# ES32F0xx register map
File version: 1.0
Registers are 32-bit, read-write, reset 0x0 unless marked. A register's access mark holds for its fields unless they carry their own. Offsets are from the block's base; [hi:lo] are bit positions; {n}, {i} and the like mark numbered series.

## GPIOA — General purpose I/O
Base 0x40084000
Same registers: GPIOB 0x40084040, GPIOC 0x40084080, GPIOD 0x400840C0, GPIOE 0x40084100, GPIOF 0x40084140, GPIOG 0x40084180, GPIOH 0x400841C0
0x00 DIN read
  [15:0] DIN
0x04 DOUT
  [15:0] DOUT
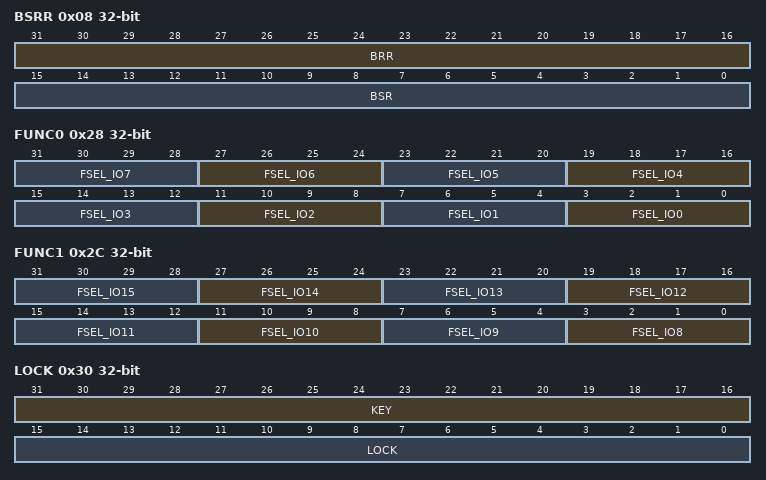
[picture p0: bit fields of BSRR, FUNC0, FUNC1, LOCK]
0x08 BSRR write
  [31:16] BRR, [15:0] BSR
0x0C BIR write
  [15:0] BIR
0x10 MODE
0x14 ODOS
0x18 PUPD
0x1C ODRV reset 0xAAAAAAAA
0x20 FLT
  [15:0] FLT
0x24 TYPE
  [15:0] TYPE
0x28 FUNC0
  [4n+3:4n] FSEL_IO{n} (n=0..7)
0x2C FUNC1
  [4n-29:4n-32] FSEL_IO{n} (n=8..15)
0x30 LOCK
  [31:16] KEY, [15:0] LOCK

## EXTI — External Interrupt
Base 0x40084300
0x00 EXTIRER
  [15:0] EXTIRER
0x08 EXTIFER
  [15:0] EXTIFER
0x10 EXTIEN
  [15:0] EXTIEN
0x18 EXTIFLAG read
  [15:0] EXTIFLAG
0x20 EXTISFR write
  [15:0] EXTISFR
0x28 EXTICFR write
  [15:0] EXTICFR
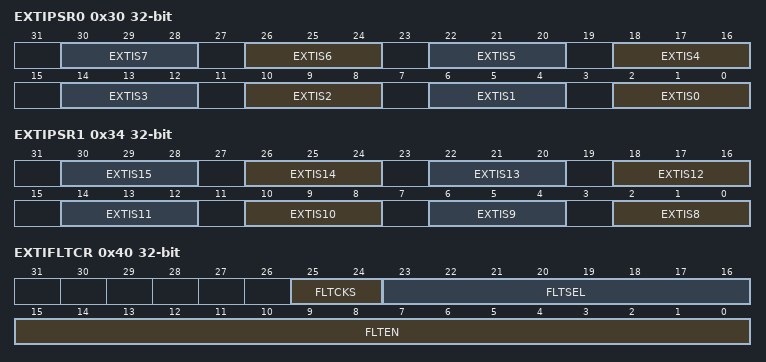
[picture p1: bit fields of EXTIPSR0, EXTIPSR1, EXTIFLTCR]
0x30 EXTIPSR0
  [4n+2:4n] EXTIS{n} (n=0..7)
0x34 EXTIPSR1
  [4n-30:4n-32] EXTIS{n} (n=8..15)
0x40 EXTIFLTCR
  [25:24] FLTCKS, [23:16] FLTSEL, [15:0] FLTEN

## AD16C4T0 — Timer 0
Base 0x40000000
Same registers: BS16T0 0x40000400, GP16C2T0 0x40000800, GP16C2T1 0x40000C00, BS16T1 0x40001000, BS16T2 0x40001400, GP16C4T0 0x40001800, BS16T3 0x40001C00
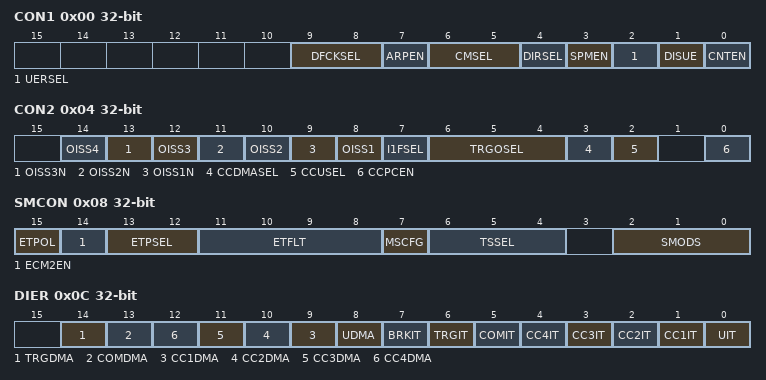
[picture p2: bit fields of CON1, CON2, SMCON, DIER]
0x00 CON1
  [9:8] DFCKSEL, [7] ARPEN, [6:5] CMSEL, [4] DIRSEL, [3] SPMEN, [2] UERSEL, [1] DISUE, [0] CNTEN
0x04 CON2
  [2n+6] OISS{n} (n=1..4), [13] OISS3N, [11] OISS2N, [9] OISS1N, [7] I1FSEL, [6:4] TRGOSEL, [3] CCDMASEL, [2] CCUSEL, [0] CCPCEN
0x08 SMCON
  [15] ETPOL, [14] ECM2EN, [13:12] ETPSEL, [11:8] ETFLT, [7] MSCFG, [6:4] TSSEL, [2:0] SMODS
0x0C DIER write
  [14] TRGDMA, [13] COMDMA, [n+8] CC{n}DMA (n=1..4), [8] UDMA, [7] BRKIT, [6] TRGIT, [5] COMIT, [n] CC{n}IT (n=1..4), [0] UIT
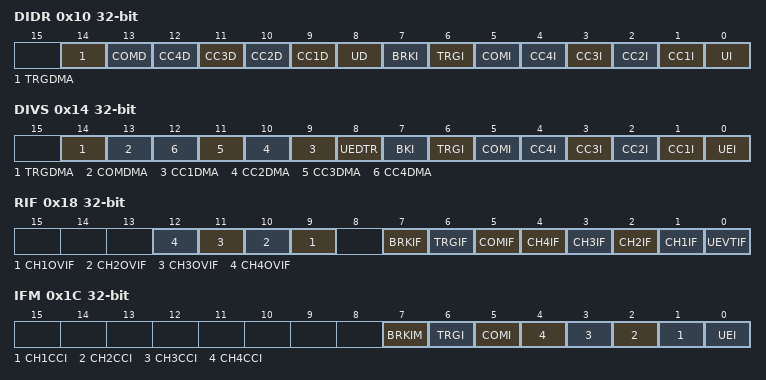
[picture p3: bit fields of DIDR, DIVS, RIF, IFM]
0x10 DIDR write
  [14] TRGDMA, [13] COMD, [n+8] CC{n}D (n=1..4), [8] UD, [7] BRKI, [6] TRGI, [5] COMI, [n] CC{n}I (n=1..4), [0] UI
0x14 DIVS read
  [14] TRGDMA, [13] COMDMA, [n+8] CC{n}DMA (n=1..4), [8] UEDTR, [7] BKI, [6] TRGI, [5] COMI, [n] CC{n}I (n=1..4), [0] UEI
0x18 RIF read
  [n+8] CH{n}OVIF (n=1..4), [7] BRKIF, [6] TRGIF, [5] COMIF, [n] CH{n}IF (n=1..4), [0] UEVTIF
0x1C IFM read
  [7] BRKIM, [6] TRGI, [5] COMI, [n] CH{n}CCI (n=1..4), [0] UEI
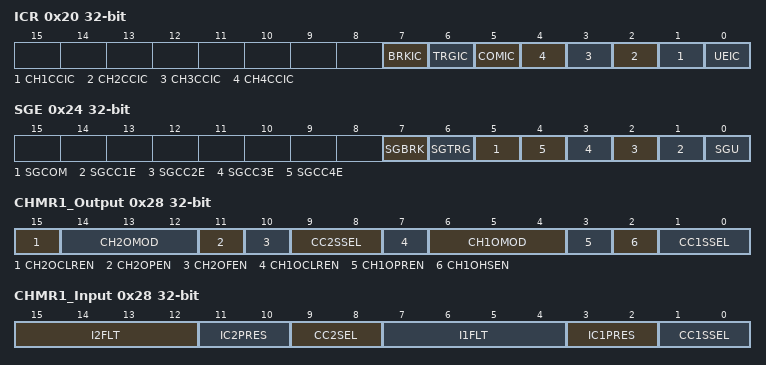
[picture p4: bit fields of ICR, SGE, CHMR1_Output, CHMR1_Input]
0x20 ICR write
  [7] BRKIC, [6] TRGIC, [5] COMIC, [n] CH{n}CCIC (n=1..4), [0] UEIC
0x24 SGE write
  [7] SGBRK, [6] SGTRG, [5] SGCOM, [n] SGCC{n}E (n=1..4), [0] SGU
0x28 CHMR1_Output
  [15] CH2OCLREN, [14:12] CH2OMOD, [11] CH2OPEN, [10] CH2OFEN, [9:8] CC2SSEL, [7] CH1OCLREN, [6:4] CH1OMOD, [3] CH1OPREN, [2] CH1OHSEN, [1:0] CC1SSEL
0x28 CHMR1_Input (alternate view of CHMR1_Output)
  [15:12] I2FLT, [11:10] IC2PRES, [9:8] CC2SEL, [7:4] I1FLT, [3:2] IC1PRES, [1:0] CC1SSEL
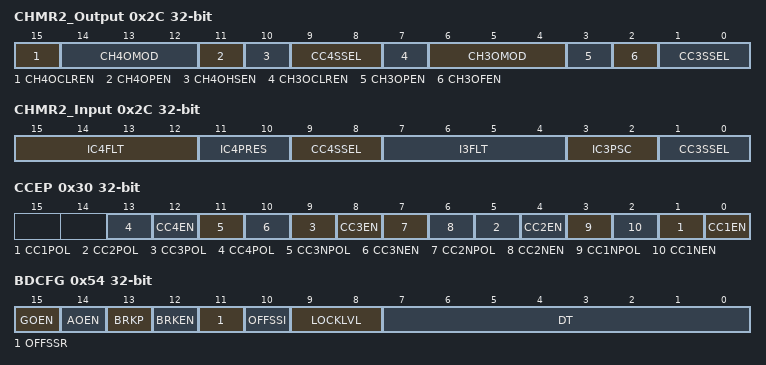
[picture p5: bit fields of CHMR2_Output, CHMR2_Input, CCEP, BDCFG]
0x2C CHMR2_Output
  [15] CH4OCLREN, [14:12] CH4OMOD, [11] CH4OPEN, [10] CH4OHSEN, [9:8] CC4SSEL, [7] CH3OCLREN, [6:4] CH3OMOD, [3] CH3OPEN, [2] CH3OFEN, [1:0] CC3SSEL
0x2C CHMR2_Input (alternate view of CHMR2_Output)
  [15:12] IC4FLT, [11:10] IC4PRES, [9:8] CC4SSEL, [7:4] I3FLT, [3:2] IC3PSC, [1:0] CC3SSEL
0x30 CCEP
  [4n-3] CC{n}POL (n=1..4), [4n-4] CC{n}EN (n=1..4), [11] CC3NPOL, [10] CC3NEN, [7] CC2NPOL, [6] CC2NEN, [3] CC1NPOL, [2] CC1NEN
0x34 COUNT
  [15:0] CNTV
0x38 PRES
  [15:0] PSCV
0x3C AR
  [15:0] ARRV
0x40 REPAR
  [7:0] REPV
{0x40+4i} CCVAL{i} (i=1..4)
  [15:0] CCRV{i}
0x54 BDCFG
  [15] GOEN, [14] AOEN, [13] BRKP, [12] BRKEN, [11] OFFSSR, [10] OFFSSI, [9:8] LOCKLVL, [7:0] DT

## SPI0 — Serial Peripheral Interface
Base 0x40006000
Same registers: SPI1 0x40006400, SPI2 0x40006800
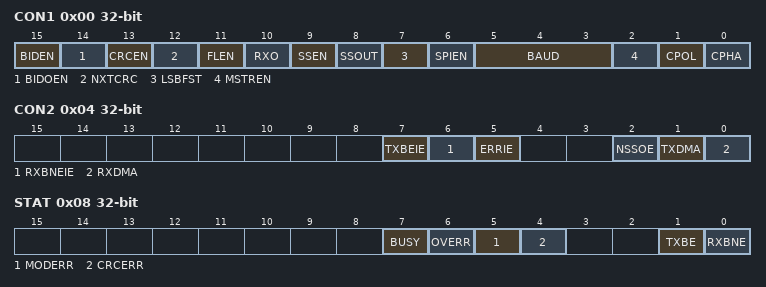
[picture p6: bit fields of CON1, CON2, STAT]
0x00 CON1
  [15] BIDEN, [14] BIDOEN, [13] CRCEN, [12] NXTCRC, [11] FLEN, [10] RXO, [9] SSEN, [8] SSOUT, [7] LSBFST, [6] SPIEN, [5:3] BAUD, [2] MSTREN, [1] CPOL, [0] CPHA
0x04 CON2
  [7] TXBEIE, [6] RXBNEIE, [5] ERRIE, [2] NSSOE, [1] TXDMA, [0] RXDMA
0x08 STAT read
  [7] BUSY, [6] OVERR, [5] MODERR, [4] CRCERR, [1] TXBE, [0] RXBNE
0x0C DATA
  [15:0] VALUE
0x10 CRCPOLY reset 0x7
  [15:0] VALUE
0x14 RXCRC read
  [15:0] CRCVAL
0x18 TXCRC read
  [15:0] CRCVAL
